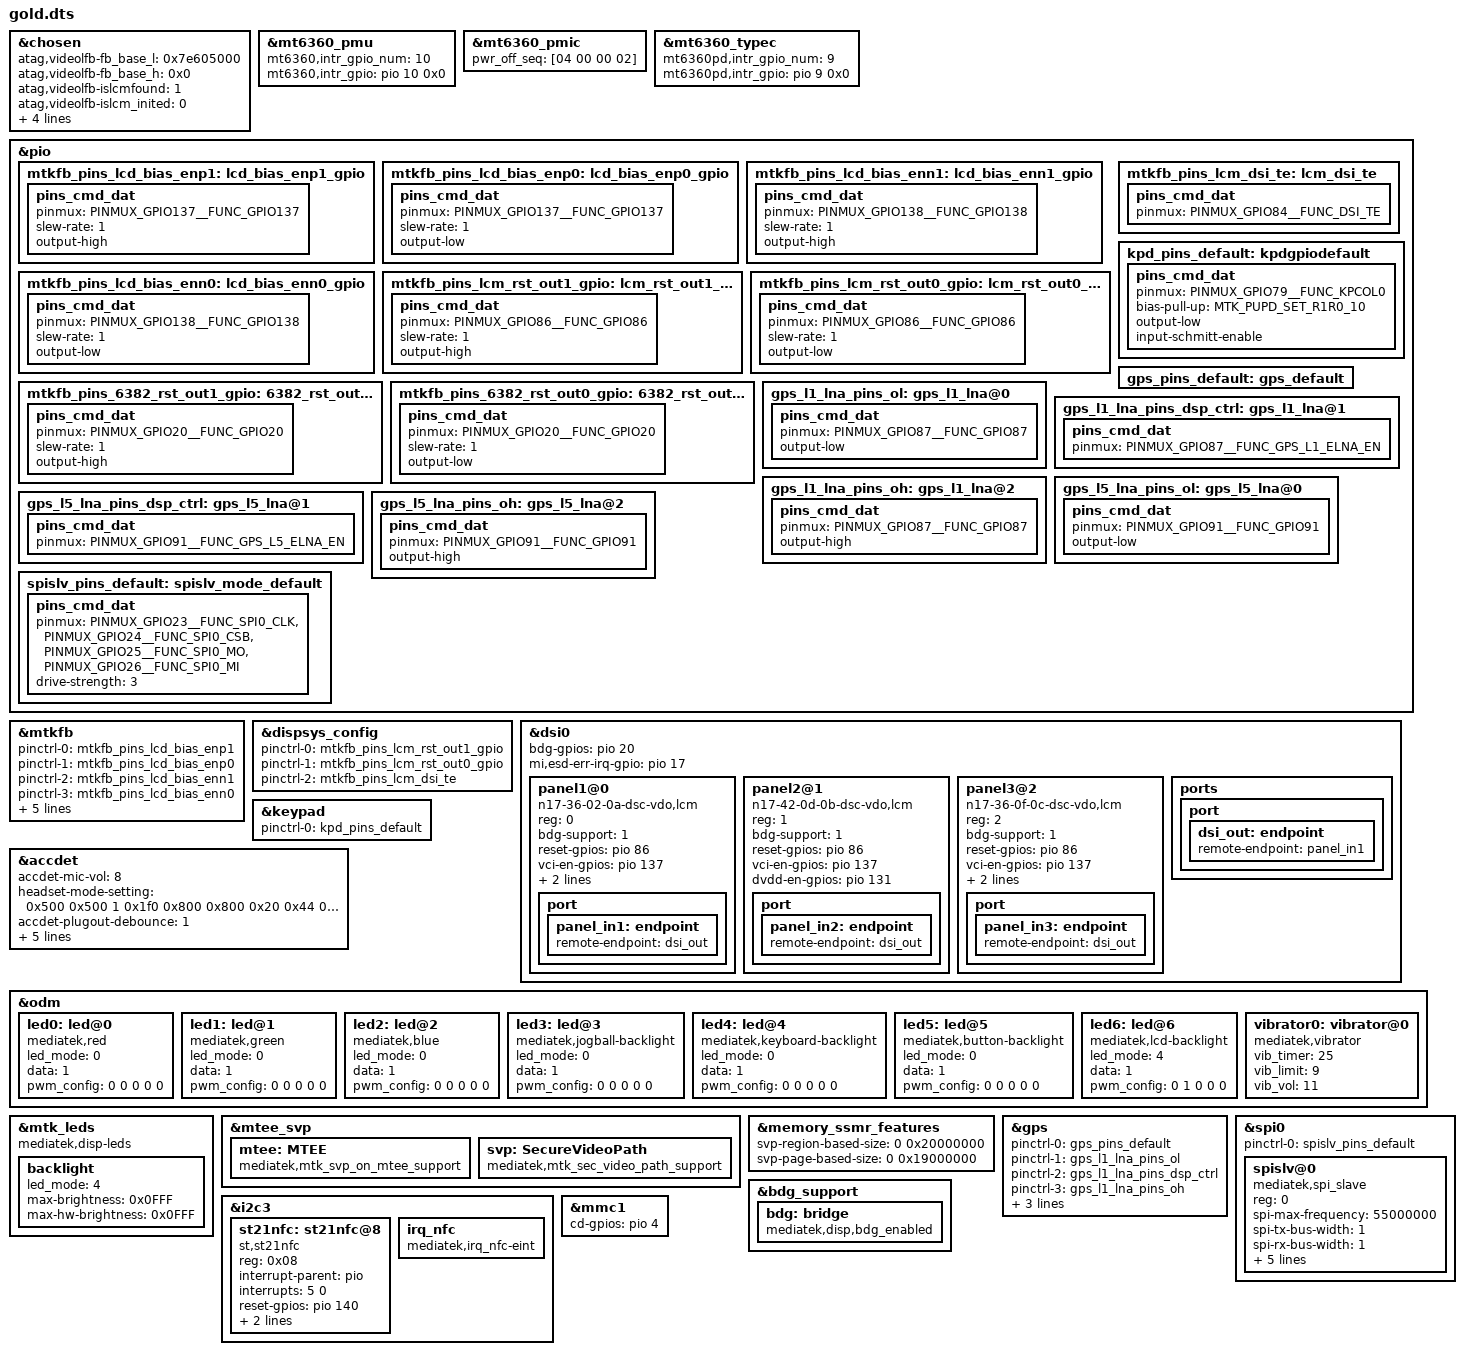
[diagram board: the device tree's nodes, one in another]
// SPDX-License-Identifier: GPL-2.0
/*
 * Copyright (c) 2019 MediaTek Inc.
 *
 */
/dts-v1/;
/plugin/;
#include <dt-bindings/interrupt-controller/irq.h>
#include <dt-bindings/interrupt-controller/arm-gic.h>
#include <dt-bindings/pinctrl/mt6833-pinfunc.h>
/* chosen */
&chosen {
	atag,videolfb-fb_base_l = <0x7e605000>;
	atag,videolfb-fb_base_h = <0x0>;
	atag,videolfb-islcmfound = <1>;
	atag,videolfb-islcm_inited = <0>;
	atag,videolfb-fps= <6000>;
	atag,videolfb-vramSize= <0x1be0000>;
	atag,videolfb-lcmname=
		"nt35595_fhd_dsi_cmd_truly_nt50358_drv";
};

&mt6360_pmu {
	mt6360,intr_gpio_num = <10>; /* direct defined GPIO num */
	mt6360,intr_gpio = <&pio 10 0x0>;
};

&mt6360_pmic {
	pwr_off_seq = [04 00 00 02];
};
/*N17 HQ-291635 adb bringup by miaozhichao at 2023/4/18 start*/
&mt6360_typec {
	mt6360pd,intr_gpio_num = <9>; /* direct defined GPIO num */
	mt6360pd,intr_gpio = <&pio 9 0x0>;
};
/*N17 HQ-291635 adb bringup by miaozhichao at 2023/4/18 end*/
&pio {
	mtkfb_pins_lcd_bias_enp1: lcd_bias_enp1_gpio {
		pins_cmd_dat {
			pinmux = <PINMUX_GPIO137__FUNC_GPIO137>;
			slew-rate = <1>;
			output-high;
		};
	};

	mtkfb_pins_lcd_bias_enp0: lcd_bias_enp0_gpio {
		pins_cmd_dat {
			pinmux = <PINMUX_GPIO137__FUNC_GPIO137>;
			slew-rate = <1>;
			output-low;
		};
	};
	mtkfb_pins_lcd_bias_enn1: lcd_bias_enn1_gpio {
		pins_cmd_dat {
			pinmux = <PINMUX_GPIO138__FUNC_GPIO138>;
			slew-rate = <1>;
			output-high;
		};
	};

	mtkfb_pins_lcd_bias_enn0: lcd_bias_enn0_gpio {
		pins_cmd_dat {
			pinmux = <PINMUX_GPIO138__FUNC_GPIO138>;
			slew-rate = <1>;
			output-low;
		};
	};

	mtkfb_pins_lcm_rst_out1_gpio: lcm_rst_out1_gpio {
		pins_cmd_dat {
			pinmux = <PINMUX_GPIO86__FUNC_GPIO86>;
			slew-rate = <1>;
			output-high;
		};
	};

	mtkfb_pins_lcm_rst_out0_gpio: lcm_rst_out0_gpio {
		pins_cmd_dat {
			pinmux = <PINMUX_GPIO86__FUNC_GPIO86>;
			slew-rate = <1>;
			output-low;
		};
	};
	mtkfb_pins_lcm_dsi_te: lcm_dsi_te {
		pins_cmd_dat {
			pinmux = <PINMUX_GPIO84__FUNC_DSI_TE>;
		};
	};
	/*N17 code for HQ-291664 by chenzimo at 2023/4/18 start*/
	mtkfb_pins_6382_rst_out1_gpio: 6382_rst_out1_gpio {
		pins_cmd_dat {
			pinmux = <PINMUX_GPIO20__FUNC_GPIO20>;
			slew-rate = <1>;
			output-high;
		};
	};

	mtkfb_pins_6382_rst_out0_gpio: 6382_rst_out0_gpio {
		pins_cmd_dat {
			pinmux = <PINMUX_GPIO20__FUNC_GPIO20>;
			slew-rate = <1>;
			output-low;
		};
	};
	/*N17 code for HQ-291664 by chenzimo at 2023/4/18 end*/
};

&mtkfb {
	pinctrl-names = "lcd_bias_enp1_gpio", "lcd_bias_enp0_gpio",
		"lcd_bias_enn1_gpio", "lcd_bias_enn0_gpio",
		"lcm_rst_out1_gpio", "lcm_rst_out0_gpio",
		"mode_te_te",
		"6382_rst_out1_gpio", "6382_rst_out0_gpio";
	pinctrl-0 = <&mtkfb_pins_lcd_bias_enp1>;
	pinctrl-1 = <&mtkfb_pins_lcd_bias_enp0>;
	pinctrl-2 = <&mtkfb_pins_lcd_bias_enn1>;
	pinctrl-3 = <&mtkfb_pins_lcd_bias_enn0>;
	pinctrl-4 = <&mtkfb_pins_lcm_rst_out1_gpio>;
	pinctrl-5 = <&mtkfb_pins_lcm_rst_out0_gpio>;
	pinctrl-6 = <&mtkfb_pins_lcm_dsi_te>;
	pinctrl-7 = <&mtkfb_pins_6382_rst_out1_gpio>;
	pinctrl-8 = <&mtkfb_pins_6382_rst_out0_gpio>;
	status = "okay";
};
&dispsys_config {
	pinctrl-names =
		"lcm_rst_out1_gpio", "lcm_rst_out0_gpio",
		"mode_te_te";
	pinctrl-0 = <&mtkfb_pins_lcm_rst_out1_gpio>;
	pinctrl-1 = <&mtkfb_pins_lcm_rst_out0_gpio>;
	pinctrl-2 = <&mtkfb_pins_lcm_dsi_te>;
	status = "okay";
};

/*N17 code for HQ-291664 by chenzimo at 2023/4/23 start*/
&dsi0 {
	status = "okay";
	#address-cells = <1>;
	#size-cells = <0>;
	bdg-gpios = <&pio 20 0>;
/*N17 code for HQ-299504 by p-lizongrui at 2023/06/26 start*/
	mi,esd-err-irq-gpio = <&pio 17 0x2002>;
/*N17 code for HQ-299504 by p-lizongrui at 2023/06/26 end*/
	panel1@0 {
		compatible = "n17-36-02-0a-dsc-vdo,lcm";
		reg = <0>;
		bdg-support=<1>;
		reset-gpios = <&pio 86 0>;
		vci-en-gpios = <&pio 137 0>;
		dvdd-en-gpios = <&pio 131 0>;
/*N17 code for HQ-290979 by p-chenzimo at 2023/06/13 start*/
		mi,esd-err-irq-gpio = <&pio 17 0x2002>;
/*N17 code for HQ-290979 by p-chenzimo at 2023/06/13 end*/
		pinctrl-names = "default";
		port {
			panel_in1: endpoint {
				remote-endpoint = <&dsi_out>;
/*N17 code for HQ-291669 by p-lizongrui at 2023/05/29 start*/
			};
		};
	};
	panel2@1 {
		compatible = "n17-42-0d-0b-dsc-vdo,lcm";
		reg = <1>;
		bdg-support=<1>;
		reset-gpios = <&pio 86 0>;
		vci-en-gpios = <&pio 137 0>;
		dvdd-en-gpios = <&pio 131 0>;
		pinctrl-names = "default";
		port {
			panel_in2: endpoint {
				remote-endpoint = <&dsi_out>;
/*N17 code for HQ-291669 by p-lizongrui at 2023/05/29 end*/
			};
		};
	};
/*N17 code for HQ-298851 by p-lizongrui at 2023/06/08 start*/
	panel3@2 {
		compatible = "n17-36-0f-0c-dsc-vdo,lcm";
		reg = <2>;
		bdg-support = <1>;
		reset-gpios = <&pio 86 0>;
		vci-en-gpios = <&pio 137 0>;
		dvdd-en-gpios = <&pio 131 0>;
		pinctrl-names = "default";
		dbv-table = <0>;
		port {
			panel_in3: endpoint {
				remote-endpoint = <&dsi_out>;
			};
		};
	};
/*N17 code for HQ-298851 by p-lizongrui at 2023/06/08 end*/
	ports {
		port {
			dsi_out: endpoint {
				remote-endpoint = <&panel_in1>;
			};
		};
	};
};
/*N17 code for HQ-291664 by chenzimo at 2023/4/23 end*/

&keypad {
	pinctrl-names = "default";
	pinctrl-0 = <&kpd_pins_default>;
};

&pio {
	kpd_pins_default: kpdgpiodefault {
		pins_cmd_dat {
			pinmux = <PINMUX_GPIO79__FUNC_KPCOL0>;
			bias-pull-up = <MTK_PUPD_SET_R1R0_10>;
			output-low;
			input-schmitt-enable;
		};
	};
};

/*N17 code for HQ-291658 by gaoxue at 2023/4/18 start*/
/*#include "mediatek/cust_mt6833_touch_120hz.dtsi"*/
#include "mediatek/cust_mt6833_touch_1080x2400.dtsi"
/*N17 code for HQ-291658 by gaoxue at 2023/4/18 end*/

/* accdet start */
&accdet {
	/* accdet micbias voltage: 0x09:2.85v 0x08:2.8v 0x07,
	 * 2.7v;0x05,2.5v;0x02,1.9v
	 */
	accdet-mic-vol = <8>;
	/* accdet pwm_width, pwm_thresh, fall_delay, rise_delay
	 * debounce0, debounce1, debounce3, debounce4
	 * eint pwm_width, eint pwm_thresh
	 * eint deb(debounce0, debounce1, debounce2, debounce3), inv_debounce
	 */
	headset-mode-setting = <0x500 0x500 1 0x1f0
				0x800 0x800 0x20 0x44
				0x4 0x1
				0x5 0x3 0x3 0x5 0xe>;
	accdet-plugout-debounce = <1>;
	/*1:ACC mode, 2:low cost without in bias, 6:low cost with in bias*/
	accdet-mic-mode = <2>;
	/*0--MD_MAX--UP_MAX--DW_MAX*/
	headset-three-key-threshold = <0 80 220 400>;
	headset-three-key-threshold-CDD = <0 121 192 600>;
	/*0--MD_MAX--VOICE_MAX--UP_MAX--DW_MAX*/
	headset-four-key-threshold = <0 58 121 192 400>;

	/* select VTH to 2v and 500k, use internal resitance */
	eint_use_ext_res = <0>;
	status = "okay";
};
/* accdet end */

&odm {
	led0:led@0 {
		compatible = "mediatek,red";
		led_mode = <0>;
		data = <1>;
		pwm_config = <0 0 0 0 0>;
	};
	led1:led@1 {
		compatible = "mediatek,green";
		led_mode = <0>;
		data = <1>;
		pwm_config = <0 0 0 0 0>;
	};
	led2:led@2 {
		compatible = "mediatek,blue";
		led_mode = <0>;
		data = <1>;
		pwm_config = <0 0 0 0 0>;
	};
	led3:led@3 {
		compatible = "mediatek,jogball-backlight";
		led_mode = <0>;
		data = <1>;
		pwm_config = <0 0 0 0 0>;
	};
	led4:led@4 {
		compatible = "mediatek,keyboard-backlight";
		led_mode = <0>;
		data = <1>;
		pwm_config = <0 0 0 0 0>;
	};
	led5:led@5 {
		compatible = "mediatek,button-backlight";
		led_mode = <0>;
		data = <1>;
		pwm_config = <0 0 0 0 0>;
	};
	led6:led@6 {
		compatible = "mediatek,lcd-backlight";
/*N17 code for HQ-292295 by p-lizongrui at 2023/05/16 start*/
		led_mode = <4>;
/*N17 code for HQ-292295 by p-lizongrui at 2023/05/16 end*/
		data = <1>;
		pwm_config = <0 1 0 0 0>;
	};
/* N17 code for HQ-291654 by yangjinhao at 2023/4/22 start */
	vibrator0:vibrator@0 {
		compatible = "mediatek,vibrator";
		vib_timer = <25>;
		vib_limit = <9>;
		vib_vol= <11>;
	};
/* N17 code for HQ-291654 by yangjinhao at 2023/4/22 end */
};
&mtk_leds {
/*N17 code for HQ-292295 by p-lizongrui at 2023/05/16 start*/
	compatible = "mediatek,disp-leds";
/*N17 code for HQ-292295 by p-lizongrui at 2023/05/16 end*/
	backlight {
/*N17 code for HQ-292295 by p-lizongrui at 2023/05/16 start*/
		led_mode = <4>;
		max-brightness = <0x0FFF>;
		max-hw-brightness = <0x0FFF>;
/*N17 code for HQ-292295 by p-lizongrui at 2023/05/16 end*/
	};
};

/* N17 code for widevine by lidazhuang at 2023/08/22 start*/
&mtee_svp {
        mtee: MTEE {
                compatible = "mediatek,mtk_svp_on_mtee_support";
        };
        svp: SecureVideoPath {
                compatible = "mediatek,mtk_sec_video_path_support";
        };
};

&memory_ssmr_features {
        svp-region-based-size = <0 0x20000000>;
        svp-page-based-size = <0 0x19000000>;
};
/* N17 code for widevine by lidazhuang at 2023/08/22 end*/

/* GPS GPIO standardization start */
&pio {
	gps_pins_default: gps_default {
	};

	gps_l1_lna_pins_ol: gps_l1_lna@0 {
		pins_cmd_dat {
			pinmux = <PINMUX_GPIO87__FUNC_GPIO87>;
			output-low;
		};
	};
	gps_l1_lna_pins_dsp_ctrl: gps_l1_lna@1 {
		pins_cmd_dat {
			pinmux = <PINMUX_GPIO87__FUNC_GPS_L1_ELNA_EN>;
		};
	};
	gps_l1_lna_pins_oh: gps_l1_lna@2 {
		pins_cmd_dat {
			pinmux = <PINMUX_GPIO87__FUNC_GPIO87>;
			output-high;
		};
	};

	gps_l5_lna_pins_ol: gps_l5_lna@0 {
		pins_cmd_dat {
			pinmux = <PINMUX_GPIO91__FUNC_GPIO91>;
			output-low;
		};
	};
	gps_l5_lna_pins_dsp_ctrl: gps_l5_lna@1 {
		pins_cmd_dat {
			pinmux = <PINMUX_GPIO91__FUNC_GPS_L5_ELNA_EN>;
		};
	};
	gps_l5_lna_pins_oh: gps_l5_lna@2 {
		pins_cmd_dat {
			pinmux = <PINMUX_GPIO91__FUNC_GPIO91>;
			output-high;
		};
	};
};

&gps {
	pinctrl-names = "default",
		"gps_l1_lna_disable",
		"gps_l1_lna_dsp_ctrl",
		"gps_l1_lna_enable",
		"gps_l5_lna_disable",
		"gps_l5_lna_dsp_ctrl",
		"gps_l5_lna_enable";
	pinctrl-0 = <&gps_pins_default>;
	pinctrl-1 = <&gps_l1_lna_pins_ol>;
	pinctrl-2 = <&gps_l1_lna_pins_dsp_ctrl>;
	pinctrl-3 = <&gps_l1_lna_pins_oh>;
	pinctrl-4 = <&gps_l5_lna_pins_ol>;
	pinctrl-5 = <&gps_l5_lna_pins_dsp_ctrl>;
	pinctrl-6 = <&gps_l5_lna_pins_oh>;
	status = "okay";
};
/* GPS GPIO standardization end */
		/* N17 code for HQ-290883 by zhangyize at 2023.4.19 start */
&i2c3 {
		st21nfc:st21nfc@8 {
			compatible = "st,st21nfc";
			reg = <0x08>;
			interrupt-parent = <&pio>;
  			interrupts = <5 0>;
			reset-gpios = <&pio 140 0x00>;
			irq-gpios = <&pio 5 0x00>;
			clkreq-gpios = <&pio 81 0x00>;
			status = "ok";
		};
		irq_nfc: irq_nfc {
			compatible = "mediatek,irq_nfc-eint";
		};
};
		/* N17 code for HQ-290883 by zhangyize at 2023.4.19 end */
/*N17 code for HQ-291664 by chenzimo at 2023/4/18 start*/
&spi0 {
	status = "okay";
	#address-cells = <1>;
	#size-cells = <0>;
	pinctrl-names = "default";
	pinctrl-0 = <&spislv_pins_default>;

	spislv@0 {
		compatible = "mediatek,spi_slave";
		reg = <0>;
		spi-max-frequency = <55000000>;
		spi-tx-bus-width = <1>;
		spi-rx-bus-width = <1>;
		low-speed-tick-delay = /bits/ 8 <4>;
		low-speed-early-trans = /bits/ 8 <0>;
		high-speed-tick-delay = /bits/ 8 <2>;
		high-speed-early-trans = /bits/ 8 <0>;
		slave-drive-strength = /bits/ 8 <3>;
	};
};

/*N17 code for HQ-291664 by chenzimo at 2023/4/18 end*/
&pio {
	spislv_pins_default: spislv_mode_default {
		pins_cmd_dat {
			/*N17 code for HQ-291664 by chenzimo at 2023/4/18 start*/
			pinmux = <PINMUX_GPIO23__FUNC_SPI0_CLK>,
				<PINMUX_GPIO24__FUNC_SPI0_CSB>,
				<PINMUX_GPIO25__FUNC_SPI0_MO>,
				<PINMUX_GPIO26__FUNC_SPI0_MI>;
			/*N17 code for HQ-291664 by chenzimo at 2023/4/18 end*/
			drive-strength = <3>;
		};
	};
};

&bdg_support {
	bdg: bridge {
		compatible = "mediatek,disp,bdg_enabled";
	};
};

/* N17 code for HQ-293392 by tongjiacheng at 2022/04/27 start */
#include "mediatek/auth_battery.dtsi"
/* N17 code for HQ-293392 by tongjiacheng at 2022/04/27 end */

/*N17 code for HQ-291623 by gaoshilin at 20230411 start*/
#include <dt-bindings/gpio/gpio.h>
&mmc1 {
	cd-gpios = <&pio 4 GPIO_ACTIVE_HIGH>;
};
/*N17 code for HQ-291623 by gaoshilin at 20230411 end*/

/*N17 code for HQ-291625 by miaozhichao at 2023/04/26 start*/
#include "mediatek/sc8551.dtsi"
#include "mediatek/ln8000.dtsi"
/*N17 code for HQ-291625 by miaozhichao at 2023/04/26 end*/

/* N17 code for HQ-293325 by miaozhongshu at 2023/04/21 start */
#include "mediatek/cust_mt6833_gold_camera.dtsi"
/* N17 code for HQ-293325 by miaozhongshu at 2023/04/21 end */
#include <gold/cust.dtsi>
/* N17 code for HQ-291622 by zhouchenghua at 2023/4/25 start */
#include "mediatek/gold-sia8159.dtsi"
/* N17 code for HQ-291622 by zhouchenghua at 2023/4/25 end */

/* N17 code for HQ-291641 by zhujingyi at 2023/05/08 start*/
#include "mediatek/cust_mt6833_fingerprint.dtsi"
/* N17 code for HQ-291641 by zhujingyi at 2023/05/08 end*/

/*End of this file, DO NOT ADD ANYTHING HERE*/
